# RZN2L register map
Vendor: Renesas Electronics Corporation; Series: RZN; File version: 1.30.01
CPU: other r0p0, little endian, MPU, no FPU, VTOR, 4 interrupt priority bits, 624 interrupts
Registers are 32-bit, read-write, reset 0x0 unless marked. A register's access mark holds for its fields unless they carry their own. Offsets are from the block's base; [hi:lo] are bit positions; {n}, {i} and the like mark numbered series; 'fields as' and 'values as' point back to an identical list.

## CLMA0 — Clock Monitor Circuit 0
Base 0x81280800
Same registers: CLMA1 0x81280820, CLMA2 0x81280840, CLMA3 0x81280860
0x00 CTL0 8-bit — CLMA Control Register 0
  [0] CLME — Clock Monitor m Enable (m = 0 to 3)
    0=Disables CLMAm operation; 1=Enables CLMAm operation
0x08 CMPL 16-bit reset 0x1 — CLMA Compare Register L
  [11:0] CMPL — Clock Monitor m Compare L (m = 0 to 3)
0x0C CMPH 16-bit reset 0x3FF — CLMA Compare Register H
  [11:0] CMPH — Clock Monitor m Compare H (m = 0 to 3)
0x10 PCMD 8-bit wo reset 0xFF — CLMA Command Register
0x14 PROTSR 8-bit ro — CLMA Protection Status Register
  [0] PRERR — CLMAm Error (m = 0 to 3)
    0=No protection error occurred; 1=A protection error occurred

## MPU0 — Master MPU 0
Base 0x81281100
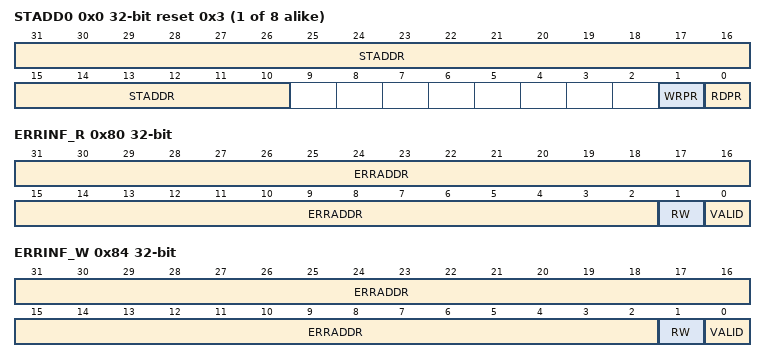
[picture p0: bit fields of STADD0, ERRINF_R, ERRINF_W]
{0x0+0x10*i} STADD{i} (i=0..7) reset 0x3 — Master MPU Safety Region Start Address Register {i}
  [31:10] STADDR — Start address for MPU region
  [1] WRPR — Enable write protection for region m of master MPU
    0=Disable write protection. Write access to the safety region is permitted.; 1=Enable write protection. Write access to the safety region is protected and error is generated.
  [0] RDPR — Enable read protection for region m of master MPU
    0=Disable read protection. Read access to the safety region is permitted.; 1=Enable read protection. Read access to the safety region is protected and error is generated.
{0x4+0x10*i} ENDADD{i} (i=0..7) reset 0xFFFFFC00 — Master MPU Safety Region End Address Register {i}
  [31:10] ENDADDR — End address for MPU region
0x80 ERRINF_R — Master MPU Error Information Register for AXI type
  [31:2] ERRADDR ro — Access error address
  [1] RW ro — Access error type
    0=Read access; 1=Write access
  [0] VALID — Validity of access error information
    0=Error information is invalid; 1=Error information is valid
0x84 ERRINF_W — Master MPU Error Information Register for AXI type
  fields as ERRINF_R

## MPU1 — Master MPU 1
Base 0x81281200
Same registers: MPU2 0x81281300, MPU6 0x81281700
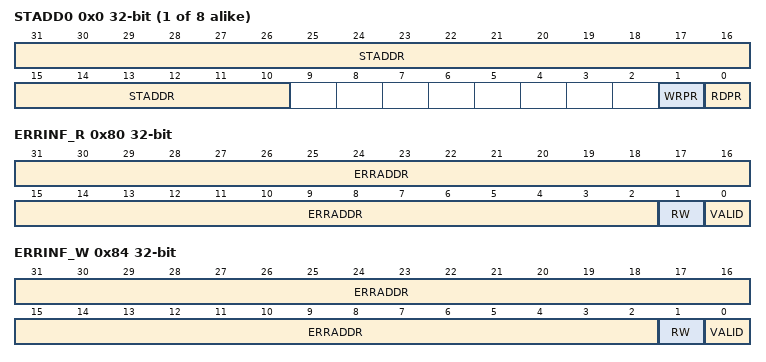
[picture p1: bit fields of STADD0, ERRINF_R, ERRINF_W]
{0x0+0x10*i} STADD{i} (i=0..7) — Master MPU Safety Region Start Address Register {i}
  [31:10] STADDR — Start address for MPU region
  [1] WRPR — Enable write protection for region m of master MPU
    0=Disable write protection. Write access to the safety region is permitted.; 1=Enable write protection. Write access to the safety region is protected and error is generated.
  [0] RDPR — Enable read protection for region m of master MPU
    0=Disable read protection. Read access to the safety region is permitted.; 1=Enable read protection. Read access to the safety region is protected and error is generated.
{0x4+0x10*i} ENDADD{i} (i=0..7) — Master MPU Safety Region End Address Register {i}
  [31:10] ENDADDR — End address for MPU region
0x80 ERRINF_R — Master MPU Error Information Register for AXI type
  [31:2] ERRADDR ro — Access error address
  [1] RW ro — Access error type
    0=Read access; 1=Write access
  [0] VALID — Validity of access error information
    0=Error information is invalid; 1=Error information is valid
0x84 ERRINF_W — Master MPU Error Information Register for AXI type
  fields as ERRINF_R

## MPU3 — Master MPU 3
Base 0x81281400
Same registers: MPU4 0x81281500, MPU7 0x81281C00, MPU8 0x81281D00
Registers as MPU1, without ERRINF_R, ERRINF_W; these are added or differ:
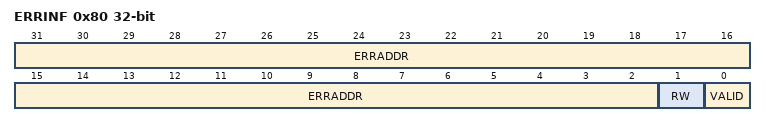
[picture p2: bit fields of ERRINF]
0x80 ERRINF — Master MPU Error Information Register for AHB type
  [31:2] ERRADDR ro — Access Error Address
  [1] RW ro — Access error type
    0=Read access; 1=Write access
  [0] VALID — Validity of Access Error Information
    0=Error information is invalid; 1=Error information is valid
